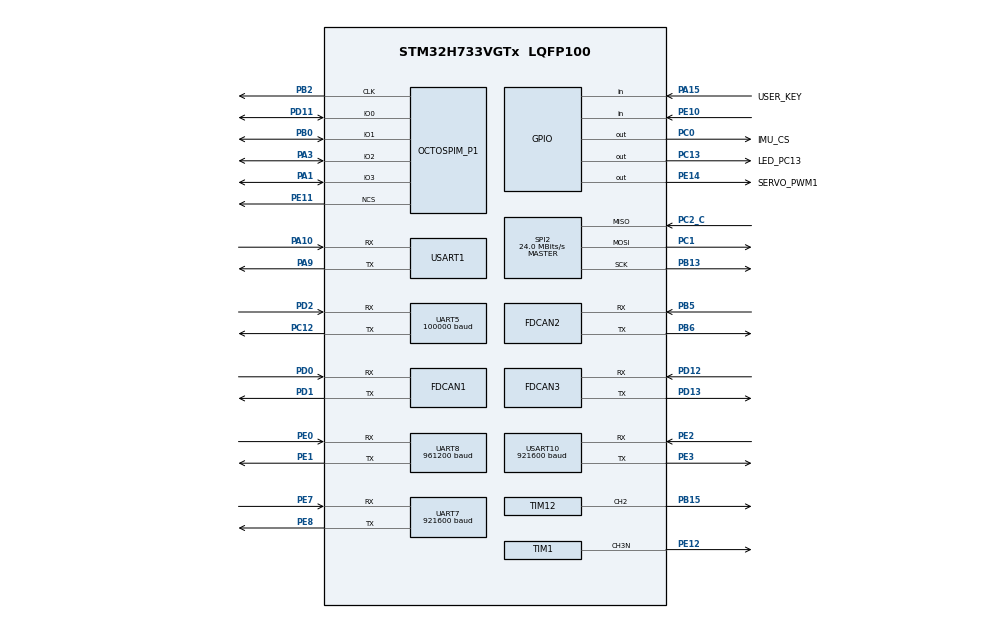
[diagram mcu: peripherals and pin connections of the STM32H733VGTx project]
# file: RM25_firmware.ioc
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CORTEX_M7.AccessPermission-Cortex_Memory_Protection_Unit_Region0_Settings=MPU_REGION_PRIV_RO
CORTEX_M7.BaseAddress-Cortex_Memory_Protection_Unit_Region0_Settings=0x08000000
CORTEX_M7.CPU_DCache=Disabled
CORTEX_M7.CPU_ICache=Enabled
CORTEX_M7.Enable-Cortex_Memory_Protection_Unit_Region0_Settings=MPU_REGION_ENABLE
CORTEX_M7.IsCacheable-Cortex_Memory_Protection_Unit_Region0_Settings=MPU_ACCESS_CACHEABLE
CORTEX_M7.MPU_Control=__NULL
CORTEX_M7.Size-Cortex_Memory_Protection_Unit_Region0_Settings=MPU_REGION_SIZE_1MB
CORTEX_M7.TypeExtField-Cortex_Memory_Protection_Unit_Region0_Settings=MPU_TEX_LEVEL1
CORTEX_M7.default_mode_Activation=0
Dma.Request0=USART1_TX
Dma.Request1=USART10_TX
Dma.Request2=UART5_RX
Dma.Request3=SPI2_TX
Dma.Request4=SPI2_RX
Dma.Request5=UART7_TX
Dma.Request6=USART1_RX
Dma.Request7=USART10_RX
Dma.Request8=UART8_RX
Dma.Request9=UART8_TX
Dma.SPI2_RX.4.Direction=DMA_PERIPH_TO_MEMORY
Dma.SPI2_RX.4.EventEnable=DISABLE
Dma.SPI2_RX.4.FIFOMode=DMA_FIFOMODE_DISABLE
Dma.SPI2_RX.4.Instance=DMA1_Stream5
Dma.SPI2_RX.4.MemDataAlignment=DMA_MDATAALIGN_BYTE
Dma.SPI2_RX.4.MemInc=DMA_MINC_ENABLE
Dma.SPI2_RX.4.Mode=DMA_NORMAL
Dma.SPI2_RX.4.PeriphDataAlignment=DMA_PDATAALIGN_BYTE
Dma.SPI2_RX.4.PeriphInc=DMA_PINC_DISABLE
Dma.SPI2_RX.4.Polarity=HAL_DMAMUX_REQ_GEN_RISING
Dma.SPI2_RX.4.Priority=DMA_PRIORITY_MEDIUM
Dma.SPI2_RX.4.RequestNumber=1
Dma.SPI2_RX.4.SignalID=NONE
Dma.SPI2_RX.4.SyncEnable=DISABLE
Dma.SPI2_RX.4.SyncPolarity=HAL_DMAMUX_SYNC_NO_EVENT
Dma.SPI2_RX.4.SyncRequestNumber=1
Dma.SPI2_RX.4.SyncSignalID=NONE
Dma.SPI2_TX.3.Direction=DMA_MEMORY_TO_PERIPH
Dma.SPI2_TX.3.EventEnable=DISABLE
Dma.SPI2_TX.3.FIFOMode=DMA_FIFOMODE_DISABLE
Dma.SPI2_TX.3.Instance=DMA1_Stream4
Dma.SPI2_TX.3.MemDataAlignment=DMA_MDATAALIGN_BYTE
Dma.SPI2_TX.3.MemInc=DMA_MINC_ENABLE
Dma.SPI2_TX.3.Mode=DMA_NORMAL
Dma.SPI2_TX.3.PeriphDataAlignment=DMA_PDATAALIGN_BYTE
Dma.SPI2_TX.3.PeriphInc=DMA_PINC_DISABLE
Dma.SPI2_TX.3.Polarity=HAL_DMAMUX_REQ_GEN_RISING
Dma.SPI2_TX.3.Priority=DMA_PRIORITY_MEDIUM
Dma.SPI2_TX.3.RequestNumber=1
Dma.SPI2_TX.3.SignalID=NONE
Dma.SPI2_TX.3.SyncEnable=DISABLE
Dma.SPI2_TX.3.SyncPolarity=HAL_DMAMUX_SYNC_NO_EVENT
Dma.SPI2_TX.3.SyncRequestNumber=1
Dma.SPI2_TX.3.SyncSignalID=NONE
Dma.UART5_RX.2.Direction=DMA_PERIPH_TO_MEMORY
Dma.UART5_RX.2.EventEnable=DISABLE
Dma.UART5_RX.2.FIFOMode=DMA_FIFOMODE_DISABLE
Dma.UART5_RX.2.Instance=DMA1_Stream3
Dma.UART5_RX.2.MemDataAlignment=DMA_MDATAALIGN_BYTE
Dma.UART5_RX.2.MemInc=DMA_MINC_ENABLE
Dma.UART5_RX.2.Mode=DMA_NORMAL
Dma.UART5_RX.2.PeriphDataAlignment=DMA_PDATAALIGN_BYTE
Dma.UART5_RX.2.PeriphInc=DMA_PINC_DISABLE
Dma.UART5_RX.2.Polarity=HAL_DMAMUX_REQ_GEN_RISING
Dma.UART5_RX.2.Priority=DMA_PRIORITY_LOW
Dma.UART5_RX.2.RequestNumber=1
Dma.UART5_RX.2.SignalID=NONE
Dma.UART5_RX.2.SyncEnable=DISABLE
Dma.UART5_RX.2.SyncPolarity=HAL_DMAMUX_SYNC_NO_EVENT
Dma.UART5_RX.2.SyncRequestNumber=1
Dma.UART5_RX.2.SyncSignalID=NONE
Dma.UART7_TX.5.Direction=DMA_MEMORY_TO_PERIPH
Dma.UART7_TX.5.EventEnable=DISABLE
Dma.UART7_TX.5.FIFOMode=DMA_FIFOMODE_DISABLE
Dma.UART7_TX.5.Instance=DMA1_Stream0
Dma.UART7_TX.5.MemDataAlignment=DMA_MDATAALIGN_BYTE
Dma.UART7_TX.5.MemInc=DMA_MINC_ENABLE
Dma.UART7_TX.5.Mode=DMA_NORMAL
Dma.UART7_TX.5.PeriphDataAlignment=DMA_PDATAALIGN_BYTE
Dma.UART7_TX.5.PeriphInc=DMA_PINC_DISABLE
Dma.UART7_TX.5.Polarity=HAL_DMAMUX_REQ_GEN_RISING
Dma.UART7_TX.5.Priority=DMA_PRIORITY_LOW
Dma.UART7_TX.5.RequestNumber=1
Dma.UART7_TX.5.SignalID=NONE
Dma.UART7_TX.5.SyncEnable=DISABLE
Dma.UART7_TX.5.SyncPolarity=HAL_DMAMUX_SYNC_NO_EVENT
Dma.UART7_TX.5.SyncRequestNumber=1
Dma.UART7_TX.5.SyncSignalID=NONE
Dma.UART8_RX.8.Direction=DMA_PERIPH_TO_MEMORY
Dma.UART8_RX.8.EventEnable=DISABLE
Dma.UART8_RX.8.FIFOMode=DMA_FIFOMODE_DISABLE
Dma.UART8_RX.8.Instance=DMA2_Stream0
Dma.UART8_RX.8.MemDataAlignment=DMA_MDATAALIGN_BYTE
Dma.UART8_RX.8.MemInc=DMA_MINC_ENABLE
Dma.UART8_RX.8.Mode=DMA_CIRCULAR
Dma.UART8_RX.8.PeriphDataAlignment=DMA_PDATAALIGN_BYTE
Dma.UART8_RX.8.PeriphInc=DMA_PINC_DISABLE
Dma.UART8_RX.8.Polarity=HAL_DMAMUX_REQ_GEN_RISING
Dma.UART8_RX.8.Priority=DMA_PRIORITY_LOW
Dma.UART8_RX.8.RequestNumber=1
Dma.UART8_RX.8.SignalID=NONE
Dma.UART8_RX.8.SyncEnable=DISABLE
Dma.UART8_RX.8.SyncPolarity=HAL_DMAMUX_SYNC_NO_EVENT
Dma.UART8_RX.8.SyncRequestNumber=1
Dma.UART8_RX.8.SyncSignalID=NONE
Dma.UART8_TX.9.Direction=DMA_MEMORY_TO_PERIPH
Dma.UART8_TX.9.EventEnable=DISABLE
Dma.UART8_TX.9.FIFOMode=DMA_FIFOMODE_DISABLE
Dma.UART8_TX.9.Instance=DMA2_Stream1
Dma.UART8_TX.9.MemDataAlignment=DMA_MDATAALIGN_BYTE
Dma.UART8_TX.9.MemInc=DMA_MINC_ENABLE
Dma.UART8_TX.9.Mode=DMA_NORMAL
Dma.UART8_TX.9.PeriphDataAlignment=DMA_PDATAALIGN_BYTE
Dma.UART8_TX.9.PeriphInc=DMA_PINC_DISABLE
Dma.UART8_TX.9.Polarity=HAL_DMAMUX_REQ_GEN_RISING
Dma.UART8_TX.9.Priority=DMA_PRIORITY_LOW
Dma.UART8_TX.9.RequestNumber=1
Dma.UART8_TX.9.SignalID=NONE
Dma.UART8_TX.9.SyncEnable=DISABLE
Dma.UART8_TX.9.SyncPolarity=HAL_DMAMUX_SYNC_NO_EVENT
Dma.UART8_TX.9.SyncRequestNumber=1
Dma.UART8_TX.9.SyncSignalID=NONE
Dma.USART10_RX.7.Direction=DMA_PERIPH_TO_MEMORY
Dma.USART10_RX.7.EventEnable=DISABLE
Dma.USART10_RX.7.FIFOMode=DMA_FIFOMODE_DISABLE
Dma.USART10_RX.7.Instance=DMA1_Stream7
Dma.USART10_RX.7.MemDataAlignment=DMA_MDATAALIGN_BYTE
Dma.USART10_RX.7.MemInc=DMA_MINC_ENABLE
Dma.USART10_RX.7.Mode=DMA_CIRCULAR
Dma.USART10_RX.7.PeriphDataAlignment=DMA_PDATAALIGN_BYTE
Dma.USART10_RX.7.PeriphInc=DMA_PINC_DISABLE
Dma.USART10_RX.7.Polarity=HAL_DMAMUX_REQ_GEN_RISING
Dma.USART10_RX.7.Priority=DMA_PRIORITY_LOW
Dma.USART10_RX.7.RequestNumber=1
Dma.USART10_RX.7.SignalID=NONE
Dma.USART10_RX.7.SyncEnable=DISABLE
Dma.USART10_RX.7.SyncPolarity=HAL_DMAMUX_SYNC_NO_EVENT
Dma.USART10_RX.7.SyncRequestNumber=1
Dma.USART10_RX.7.SyncSignalID=NONE
Dma.USART10_TX.1.Direction=DMA_MEMORY_TO_PERIPH
Dma.USART10_TX.1.EventEnable=DISABLE
Dma.USART10_TX.1.FIFOMode=DMA_FIFOMODE_DISABLE
Dma.USART10_TX.1.Instance=DMA1_Stream2
Dma.USART10_TX.1.MemDataAlignment=DMA_MDATAALIGN_BYTE
Dma.USART10_TX.1.MemInc=DMA_MINC_ENABLE
Dma.USART10_TX.1.Mode=DMA_NORMAL
Dma.USART10_TX.1.PeriphDataAlignment=DMA_PDATAALIGN_BYTE
Dma.USART10_TX.1.PeriphInc=DMA_PINC_DISABLE
Dma.USART10_TX.1.Polarity=HAL_DMAMUX_REQ_GEN_RISING
Dma.USART10_TX.1.Priority=DMA_PRIORITY_LOW
Dma.USART10_TX.1.RequestNumber=1
Dma.USART10_TX.1.SignalID=NONE
Dma.USART10_TX.1.SyncEnable=DISABLE
Dma.USART10_TX.1.SyncPolarity=HAL_DMAMUX_SYNC_NO_EVENT
Dma.USART10_TX.1.SyncRequestNumber=1
Dma.USART10_TX.1.SyncSignalID=NONE
Dma.USART1_RX.6.Direction=DMA_PERIPH_TO_MEMORY
Dma.USART1_RX.6.EventEnable=DISABLE
Dma.USART1_RX.6.FIFOMode=DMA_FIFOMODE_DISABLE
Dma.USART1_RX.6.Instance=DMA1_Stream6
Dma.USART1_RX.6.MemDataAlignment=DMA_MDATAALIGN_BYTE
Dma.USART1_RX.6.MemInc=DMA_MINC_ENABLE
Dma.USART1_RX.6.Mode=DMA_CIRCULAR
Dma.USART1_RX.6.PeriphDataAlignment=DMA_PDATAALIGN_BYTE
Dma.USART1_RX.6.PeriphInc=DMA_PINC_DISABLE
Dma.USART1_RX.6.Polarity=HAL_DMAMUX_REQ_GEN_RISING
Dma.USART1_RX.6.Priority=DMA_PRIORITY_LOW
Dma.USART1_RX.6.RequestNumber=1
Dma.USART1_RX.6.SignalID=NONE
Dma.USART1_RX.6.SyncEnable=DISABLE
Dma.USART1_RX.6.SyncPolarity=HAL_DMAMUX_SYNC_NO_EVENT
Dma.USART1_RX.6.SyncRequestNumber=1
Dma.USART1_RX.6.SyncSignalID=NONE
Dma.USART1_TX.0.Direction=DMA_MEMORY_TO_PERIPH
Dma.USART1_TX.0.EventEnable=DISABLE
Dma.USART1_TX.0.FIFOMode=DMA_FIFOMODE_DISABLE
Dma.USART1_TX.0.Instance=DMA1_Stream1
Dma.USART1_TX.0.MemDataAlignment=DMA_MDATAALIGN_BYTE
Dma.USART1_TX.0.MemInc=DMA_MINC_ENABLE
Dma.USART1_TX.0.Mode=DMA_NORMAL
Dma.USART1_TX.0.PeriphDataAlignment=DMA_PDATAALIGN_BYTE
Dma.USART1_TX.0.PeriphInc=DMA_PINC_DISABLE
Dma.USART1_TX.0.Polarity=HAL_DMAMUX_REQ_GEN_RISING
Dma.USART1_TX.0.Priority=DMA_PRIORITY_LOW
Dma.USART1_TX.0.RequestNumber=1
Dma.USART1_TX.0.SignalID=NONE
Dma.USART1_TX.0.SyncEnable=DISABLE
Dma.USART1_TX.0.SyncPolarity=HAL_DMAMUX_SYNC_NO_EVENT
Dma.USART1_TX.0.SyncRequestNumber=1
Dma.USART1_TX.0.SyncSignalID=NONE
FDCAN1.AutoRetransmission=ENABLE
FDCAN1.CalculateBaudRateNominal=1000000
FDCAN1.CalculateTimeBitNominal=1000
FDCAN1.CalculateTimeQuantumNominal=200.0
FDCAN1.NominalTimeSeg1=2
FDCAN1.NominalTimeSeg2=2
FDCAN1.RxFifo0ElmtsNbr=32
FDCAN1.StdFiltersNbr=1
FDCAN1.TxFifoQueueElmtsNbr=32
FDCAN2.AutoRetransmission=ENABLE
FDCAN2.CalculateBaudRateNominal=1000000
FDCAN2.CalculateTimeBitNominal=1000
FDCAN2.CalculateTimeQuantumNominal=200.0
FDCAN2.ClockCalibrationCCU=DISABLE
FDCAN2.MessageRAMOffset=768
FDCAN2.NominalTimeSeg1=2
FDCAN2.NominalTimeSeg2=2
FDCAN2.RxFifo0ElmtsNbr=32
FDCAN2.StdFiltersNbr=1
FDCAN2.TxFifoQueueElmtsNbr=32
FDCAN3.AutoRetransmission=ENABLE
FDCAN3.CalculateBaudRateNominal=1000000
FDCAN3.CalculateTimeBitNominal=1000
FDCAN3.CalculateTimeQuantumNominal=200.0
FDCAN3.MessageRAMOffset=1536
FDCAN3.NominalPrescaler=16
FDCAN3.NominalTimeSeg1=2
FDCAN3.NominalTimeSeg2=2
FDCAN3.RxFifo0ElmtsNbr=32
FDCAN3.StdFiltersNbr=1
FDCAN3.TxFifoQueueElmtsNbr=32
Mcu.Family=STM32H7
Mcu.Name=STM32H733VGTx
Mcu.Package=LQFP100
NVIC.DMA1_Stream0_IRQn=true\:0\:0\:false\:false\:true\:false\:true\:true
NVIC.DMA1_Stream1_IRQn=true\:0\:0\:false\:false\:true\:false\:true\:true
NVIC.DMA1_Stream2_IRQn=true\:0\:0\:false\:false\:true\:false\:true\:true
NVIC.DMA1_Stream3_IRQn=true\:0\:0\:false\:false\:true\:false\:true\:true
NVIC.DMA1_Stream4_IRQn=true\:0\:0\:false\:false\:true\:false\:true\:true
NVIC.DMA1_Stream5_IRQn=true\:0\:0\:false\:false\:true\:false\:true\:true
NVIC.DMA1_Stream6_IRQn=true\:0\:0\:false\:false\:true\:false\:true\:true
NVIC.DMA1_Stream7_IRQn=true\:0\:0\:false\:false\:true\:false\:true\:true
NVIC.DMA2_Stream0_IRQn=true\:0\:0\:false\:false\:true\:false\:true\:true
NVIC.DMA2_Stream1_IRQn=true\:0\:0\:false\:false\:true\:false\:true\:true
NVIC.FDCAN1_IT0_IRQn=true\:0\:0\:true\:false\:true\:true\:true\:true
NVIC.FDCAN1_IT1_IRQn=true\:0\:0\:true\:false\:true\:true\:true\:true
NVIC.FDCAN2_IT0_IRQn=true\:0\:0\:true\:false\:true\:true\:true\:true
NVIC.FDCAN2_IT1_IRQn=true\:0\:0\:true\:false\:true\:true\:true\:true
NVIC.FDCAN3_IT0_IRQn=true\:0\:0\:true\:false\:true\:true\:true\:true
NVIC.FDCAN3_IT1_IRQn=true\:0\:0\:true\:false\:true\:true\:true\:true
NVIC.PriorityGroup=NVIC_PRIORITYGROUP_4
NVIC.SPI2_IRQn=true\:0\:0\:false\:false\:true\:false\:true\:true
NVIC.TIM2_IRQn=true\:0\:0\:false\:false\:true\:true\:true\:true
NVIC.TIM6_DAC_IRQn=true\:5\:0\:true\:false\:true\:true\:false\:true
NVIC.TIM7_IRQn=true\:6\:0\:true\:false\:true\:true\:false\:true
NVIC.UART5_IRQn=true\:2\:0\:true\:false\:true\:true\:true\:true
NVIC.UART7_IRQn=true\:2\:0\:true\:false\:true\:true\:true\:true
NVIC.UART8_IRQn=true\:0\:0\:false\:false\:true\:true\:true\:true
NVIC.USART10_IRQn=true\:2\:0\:true\:false\:true\:true\:true\:true
NVIC.USART1_IRQn=true\:2\:0\:true\:false\:true\:true\:true\:true
OCTOSPI2.ClockMode=HAL_OSPI_CLOCK_MODE_3
OCTOSPI2.ClockPrescaler=3
OCTOSPI2.DeviceSize=23
OCTOSPI2.FifoThreshold=8
OCTOSPI2.SampleShifting=HAL_OSPI_SAMPLE_SHIFTING_HALFCYCLE
PA1.Mode=OCTOSPI2_IOL_Port1L
PA1.Signal=OCTOSPIM_P1_IO3
PA10.GPIO_PuPd=GPIO_PULLUP
PA10.Mode=Asynchronous
PA10.Signal=USART1_RX
PA13(JTMS/SWDIO).Mode=Serial_Wire
PA13(JTMS/SWDIO).Signal=DEBUG_JTMS-SWDIO
PA14(JTCK/SWCLK).Mode=Serial_Wire
PA14(JTCK/SWCLK).Signal=DEBUG_JTCK-SWCLK
PA15(JTDI).GPIO_Label=USER_KEY
PA15(JTDI).Signal=GPIO_Input
PA3.Mode=OCTOSPI2_IOL_Port1L
PA3.Signal=OCTOSPIM_P1_IO2
PA9.GPIO_PuPd=GPIO_PULLUP
PA9.Mode=Asynchronous
PA9.Signal=USART1_TX
PB0.Mode=OCTOSPI2_IOL_Port1L
PB0.Signal=OCTOSPIM_P1_IO1
PB13.Mode=Full_Duplex_Master
PB13.Signal=SPI2_SCK
PB15.Signal=S_TIM12_CH2
PB2.Mode=O2_P1_CLK
PB2.Signal=OCTOSPIM_P1_CLK
PB5.Mode=FDCAN_Activate
PB5.Signal=FDCAN2_RX
PB6.Mode=FDCAN_Activate
PB6.Signal=FDCAN2_TX
PC0.GPIO_Label=IMU_CS
PC0.GPIO_PuPd=GPIO_PULLUP
PC0.GPIO_Speed=GPIO_SPEED_FREQ_MEDIUM
PC0.PinState=GPIO_PIN_SET
PC0.Signal=GPIO_Output
PC1.Mode=Full_Duplex_Master
PC1.Signal=SPI2_MOSI
PC12.GPIO_PuPd=GPIO_NOPULL
PC12.Mode=Asynchronous
PC12.Signal=UART5_TX
PC13.GPIO_Label=LED_PC13
PC13.Signal=GPIO_Output
PC2_C.Mode=Full_Duplex_Master
PC2_C.Signal=SPI2_MISO
PD0.Mode=FDCAN_Activate
PD0.Signal=FDCAN1_RX
PD1.Mode=FDCAN_Activate
PD1.Signal=FDCAN1_TX
PD11.Mode=OCTOSPI2_IOL_Port1L
PD11.Signal=OCTOSPIM_P1_IO0
PD12.Mode=FDCAN_Activate
PD12.Signal=FDCAN3_RX
PD13.Mode=FDCAN_Activate
PD13.Signal=FDCAN3_TX
PD2.GPIO_PuPd=GPIO_PULLUP
PD2.Mode=Asynchronous
PD2.Signal=UART5_RX
PE0.GPIO_PuPd=GPIO_PULLUP
PE0.Mode=Asynchronous
PE0.Signal=UART8_RX
PE1.Mode=Asynchronous
PE1.Signal=UART8_TX
PE10.GPIO_PuPd=GPIO_PULLUP
PE10.Signal=GPIO_Input
PE11.Mode=OCTOSPI2_Port1_NCS
PE11.Signal=OCTOSPIM_P1_NCS
PE12.Mode=PWM Generation3 CH3N
PE12.Signal=TIM1_CH3N
PE14.GPIO_Label=SERVO_PWM1
PE14.GPIO_PuPd=GPIO_PULLDOWN
PE14.Signal=GPIO_Output
PE2.GPIO_PuPd=GPIO_PULLUP
PE2.Mode=Asynchronous
PE2.Signal=USART10_RX
PE3.GPIO_PuPd=GPIO_PULLUP
PE3.Mode=Asynchronous
PE3.Signal=USART10_TX
PE7.GPIO_PuPd=GPIO_PULLUP
PE7.Mode=Asynchronous
PE7.Signal=UART7_RX
PE8.Mode=Asynchronous
PE8.Signal=UART7_TX
PH0-OSC_IN.Mode=HSE-External-Oscillator
PH0-OSC_IN.Signal=RCC_OSC_IN
PH1-OSC_OUT.Mode=HSE-External-Oscillator
PH1-OSC_OUT.Signal=RCC_OSC_OUT
ProjectManager.HeapSize=0x200
ProjectManager.StackSize=0x1000
ProjectManager.TargetToolchain=Makefile
RCC.ADCFreq_Value=80000000
RCC.APB1Freq_Value=137500000
RCC.APB2Freq_Value=137500000
RCC.APB3Freq_Value=137500000
RCC.APB4Freq_Value=137500000
RCC.CortexFreq_Value=550000000
RCC.D1PPRE=RCC_APB3_DIV2
RCC.D2PPRE1=RCC_APB1_DIV2
RCC.D2PPRE2=RCC_APB2_DIV2
RCC.D3PPRE=RCC_APB4_DIV2
RCC.DIVM1=12
RCC.DIVM2=24
RCC.DIVM3=24
RCC.DIVN1=275
RCC.DIVN2=160
RCC.DIVN3=192
RCC.DIVP1=1
RCC.DIVQ1=11
RCC.FDCANCLockSelection=RCC_FDCANCLKSOURCE_PLL2
RCC.HCLKFreq_Value=275000000
RCC.HPRE=RCC_HCLK_DIV2
RCC.HSE_VALUE=24000000
RCC.PLLSourceVirtual=RCC_PLLSOURCE_HSE
RCC.SPI123CLockSelection=RCC_SPI123CLKSOURCE_PLL3
RCC.SYSCLKFreq_VALUE=550000000
RCC.SYSCLKSource=RCC_SYSCLKSOURCE_PLLCLK
RCC.SupplySource=PWR_EXTERNAL_SOURCE_SUPPLY
RCC.USBFreq_Value=50000000
SH.S_TIM12_CH2.0=TIM12_CH2,Output Compare2 CH2
SPI2.BaudRatePrescaler=SPI_BAUDRATEPRESCALER_4
SPI2.CLKPhase=SPI_PHASE_2EDGE
SPI2.CLKPolarity=SPI_POLARITY_HIGH
SPI2.CalculateBaudRate=24.0 MBits/s
SPI2.DataSize=SPI_DATASIZE_8BIT
SPI2.Direction=SPI_DIRECTION_2LINES
SPI2.Mode=SPI_MODE_MASTER
SPI2.VirtualType=VM_MASTER
TIM1.AutoReloadPreload=TIM_AUTORELOAD_PRELOAD_ENABLE
TIM1.Channel-PWM\ Generation3\ CH3N=TIM_CHANNEL_3
TIM1.OC3Preload_PWM=DISABLE
TIM1.Period=24
TIM1.Prescaler=274
TIM1.Pulse-PWM\ Generation3\ CH3N=12
TIM12.AutoReloadPreload=TIM_AUTORELOAD_PRELOAD_ENABLE
TIM12.Channel-Output\ Compare2\ CH2=TIM_CHANNEL_2
TIM12.OC2Preload=ENABLE
TIM12.OCMode_2=TIM_OCMODE_TOGGLE
TIM12.Period=249
TIM12.Prescaler=549
TIM12.Pulse-Output\ Compare2\ CH2=5
TIM2.AutoReloadPreload=TIM_AUTORELOAD_PRELOAD_ENABLE
TIM2.Channel-Output\ Compare1\ No\ Output=TIM_CHANNEL_1
TIM2.Period=19999
TIM2.Prescaler=274
TIM2.Pulse-Output\ Compare1\ No\ Output=1500
TIM6.AutoReloadPreload=TIM_AUTORELOAD_PRELOAD_ENABLE
TIM6.Period=49
TIM6.Prescaler=274
TIM7.AutoReloadPreload=TIM_AUTORELOAD_PRELOAD_ENABLE
TIM7.Period=499
TIM7.Prescaler=549
UART5.BaudRate=100000
UART5.OverrunDisableParam=UART_ADVFEATURE_OVERRUN_ENABLE
UART5.Parity=PARITY_EVEN
UART5.WordLength=WORDLENGTH_9B
UART7.BaudRate=921600
UART8.BaudRate=961200
UART8.OverrunDisableParam=UART_ADVFEATURE_OVERRUN_ENABLE
USART1.VirtualMode-Asynchronous=VM_ASYNC
USART10.BaudRate=921600
USART10.VirtualMode=VM_ASYNC
VP_MEMORYMAP_VS_MEMORYMAP.Mode=CurAppReg
VP_OCTOSPI2_VS_quad.Mode=quad_mode
VP_TIM12_VS_ClockSourceINT.Mode=Internal
VP_TIM1_VS_ClockSourceINT.Mode=Internal
VP_TIM2_VS_ClockSourceINT.Mode=Internal
VP_TIM2_VS_no_output1.Mode=Output Compare1 No Output
VP_TIM6_VS_ClockSourceINT.Mode=Enable_Timer
VP_TIM7_VS_ClockSourceINT.Mode=Enable_Timer
board=custom

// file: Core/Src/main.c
/* USER CODE BEGIN Header */
/**
  ******************************************************************************
  * @file           : main.c
  * @brief          : Main program body
  ******************************************************************************
  * @attention
  *
  * Copyright (c) 2025 STMicroelectronics.
  * All rights reserved.
  *
  * This software is licensed under terms that can be found in the LICENSE file
  * in the root directory of this software component.
  * If no LICENSE file comes with this software, it is provided AS-IS.
  *
  ******************************************************************************
  */
/* USER CODE END Header */
#include "main.h"
#include "dma.h"
#include "fdcan.h"
#include "memorymap.h"
#include "octospi.h"
#include "spi.h"
#include "tim.h"
#include "usart.h"
#include "gpio.h"

/* USER CODE BEGIN Includes */
#include <application.h>
/* USER CODE END Includes */

void SystemClock_Config(void);
void PeriphCommonClock_Config(void);

int main(void)
{

  /* Enable the CPU Cache */

  /* Enable I-Cache---------------------------------------------------------*/
  SCB_EnableICache();

  /* MCU Configuration--------------------------------------------------------*/

  /* Reset of all peripherals, Initializes the Flash interface and the Systick. */
  HAL_Init();

  /* Configure the system clock */
  SystemClock_Config();

  /* Configure the peripherals common clocks */
  PeriphCommonClock_Config();

  /* Initialize all configured peripherals */
  MX_GPIO_Init();
  MX_DMA_Init();
  MX_FDCAN1_Init();
  MX_FDCAN2_Init();
  MX_FDCAN3_Init();
  MX_TIM12_Init();
  MX_UART7_Init();
  MX_UART5_Init();
  MX_USART1_UART_Init();
  MX_USART10_UART_Init();
  MX_OCTOSPI2_Init();
  MX_SPI2_Init();
  MX_TIM7_Init();
  MX_TIM1_Init();
  MX_TIM6_Init();
  MX_TIM2_Init();
  MX_UART8_Init();
  /* USER CODE BEGIN 2 */
  robot_init();
  /* USER CODE END 2 */

  /* Infinite loop */
  /* USER CODE BEGIN WHILE */
  while (1)
  {
    robot_loop();
    /* USER CODE END WHILE */

  }
}

void SystemClock_Config(void)
{
  RCC_OscInitTypeDef RCC_OscInitStruct = {0};
  RCC_ClkInitTypeDef RCC_ClkInitStruct = {0};

  /** Supply configuration update enable
  */
  HAL_PWREx_ConfigSupply(PWR_EXTERNAL_SOURCE_SUPPLY);

  /** Configure the main internal regulator output voltage
  */
  __HAL_PWR_VOLTAGESCALING_CONFIG(PWR_REGULATOR_VOLTAGE_SCALE0);

  while(!__HAL_PWR_GET_FLAG(PWR_FLAG_VOSRDY)) {}

  /** Initializes the RCC Oscillators according to the specified parameters
  * in the RCC_OscInitTypeDef structure.
  */
  RCC_OscInitStruct.OscillatorType = RCC_OSCILLATORTYPE_HSE;
  RCC_OscInitStruct.HSEState = RCC_HSE_ON;
  RCC_OscInitStruct.PLL.PLLState = RCC_PLL_ON;
  RCC_OscInitStruct.PLL.PLLSource = RCC_PLLSOURCE_HSE;
  RCC_OscInitStruct.PLL.PLLM = 12;
  RCC_OscInitStruct.PLL.PLLN = 275;
  RCC_OscInitStruct.PLL.PLLP = 1;
  RCC_OscInitStruct.PLL.PLLQ = 11;
  RCC_OscInitStruct.PLL.PLLR = 2;
  RCC_OscInitStruct.PLL.PLLRGE = RCC_PLL1VCIRANGE_1;
  RCC_OscInitStruct.PLL.PLLVCOSEL = RCC_PLL1VCOWIDE;
  RCC_OscInitStruct.PLL.PLLFRACN = 0;
  if (HAL_RCC_OscConfig(&RCC_OscInitStruct) != HAL_OK)
  {
    Error_Handler();
  }

  /** Initializes the CPU, AHB and APB buses clocks
  */
  RCC_ClkInitStruct.ClockType = RCC_CLOCKTYPE_HCLK|RCC_CLOCKTYPE_SYSCLK
                              |RCC_CLOCKTYPE_PCLK1|RCC_CLOCKTYPE_PCLK2
                              |RCC_CLOCKTYPE_D3PCLK1|RCC_CLOCKTYPE_D1PCLK1;
  RCC_ClkInitStruct.SYSCLKSource = RCC_SYSCLKSOURCE_PLLCLK;
  RCC_ClkInitStruct.SYSCLKDivider = RCC_SYSCLK_DIV1;
  RCC_ClkInitStruct.AHBCLKDivider = RCC_HCLK_DIV2;
  RCC_ClkInitStruct.APB3CLKDivider = RCC_APB3_DIV2;
  RCC_ClkInitStruct.APB1CLKDivider = RCC_APB1_DIV2;
  RCC_ClkInitStruct.APB2CLKDivider = RCC_APB2_DIV2;
  RCC_ClkInitStruct.APB4CLKDivider = RCC_APB4_DIV2;

  if (HAL_RCC_ClockConfig(&RCC_ClkInitStruct, FLASH_LATENCY_3) != HAL_OK)
  {
    Error_Handler();
  }
}

void PeriphCommonClock_Config(void)
{
  RCC_PeriphCLKInitTypeDef PeriphClkInitStruct = {0};

  /** Initializes the peripherals clock
  */
  PeriphClkInitStruct.PeriphClockSelection = RCC_PERIPHCLK_FDCAN;
  PeriphClkInitStruct.PLL2.PLL2M = 24;
  PeriphClkInitStruct.PLL2.PLL2N = 160;
  PeriphClkInitStruct.PLL2.PLL2P = 2;
  PeriphClkInitStruct.PLL2.PLL2Q = 2;
  PeriphClkInitStruct.PLL2.PLL2R = 2;
  PeriphClkInitStruct.PLL2.PLL2RGE = RCC_PLL2VCIRANGE_0;
  PeriphClkInitStruct.PLL2.PLL2VCOSEL = RCC_PLL2VCOMEDIUM;
  PeriphClkInitStruct.PLL2.PLL2FRACN = 0;
  PeriphClkInitStruct.FdcanClockSelection = RCC_FDCANCLKSOURCE_PLL2;
  if (HAL_RCCEx_PeriphCLKConfig(&PeriphClkInitStruct) != HAL_OK)
  {
    Error_Handler();
  }
}

void Error_Handler(void)
{
  __disable_irq();
  while (1)
  {
  }
}
